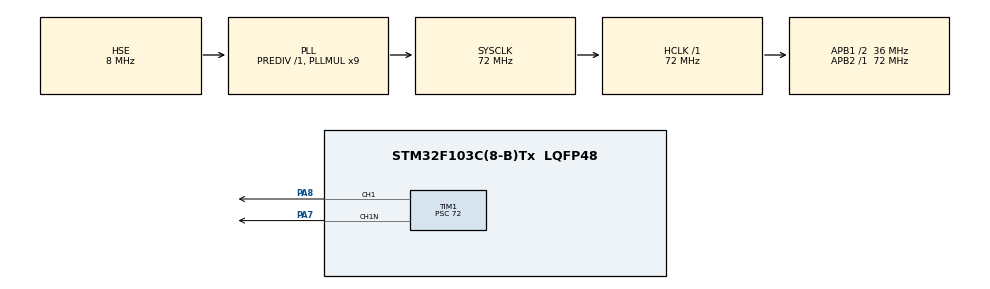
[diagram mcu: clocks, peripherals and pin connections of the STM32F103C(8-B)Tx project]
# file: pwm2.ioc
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Mcu.Family=STM32F1
Mcu.Name=STM32F103C(8-B)Tx
Mcu.Package=LQFP48
NVIC.PriorityGroup=NVIC_PRIORITYGROUP_4
PA13.Mode=Serial_Wire
PA13.Signal=SYS_JTMS-SWDIO
PA14.Mode=Serial_Wire
PA14.Signal=SYS_JTCK-SWCLK
PA7.Mode=PWM Generation1 CH1 CH1N
PA7.Signal=TIM1_CH1N
PA8.Signal=S_TIM1_CH1
PD0-OSC_IN.Mode=HSE-External-Oscillator
PD0-OSC_IN.Signal=RCC_OSC_IN
PD1-OSC_OUT.Mode=HSE-External-Oscillator
PD1-OSC_OUT.Signal=RCC_OSC_OUT
ProjectManager.HeapSize=0x200
ProjectManager.StackSize=0x400
ProjectManager.TargetToolchain=SW4STM32
RCC.AHBFreq_Value=72000000
RCC.APB1CLKDivider=RCC_HCLK_DIV2
RCC.APB1Freq_Value=36000000
RCC.APB1TimFreq_Value=72000000
RCC.APB2Freq_Value=72000000
RCC.APB2TimFreq_Value=72000000
RCC.HCLKFreq_Value=72000000
RCC.PLLMUL=RCC_PLL_MUL9
RCC.PLLSourceVirtual=RCC_PLLSOURCE_HSE
RCC.SYSCLKFreq_VALUE=72000000
RCC.SYSCLKSource=RCC_SYSCLKSOURCE_PLLCLK
RCC.USBFreq_Value=72000000
SH.S_TIM1_CH1.0=TIM1_CH1,PWM Generation1 CH1 CH1N
TIM1.Channel-PWM\ Generation1\ CH1\ CH1N=TIM_CHANNEL_1
TIM1.Period=1000
TIM1.Prescaler=72
board=custom

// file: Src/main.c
/**
  ******************************************************************************
  * @file           : main.c
  * @brief          : Main program body
  ******************************************************************************
  ** This notice applies to any and all portions of this file
  * that are not between comment pairs USER CODE BEGIN and
  * USER CODE END. Other portions of this file, whether
  * inserted by the user or by software development tools
  * are owned by their respective copyright owners.
  *
  * COPYRIGHT(c) 2018 STMicroelectronics
  *
  * Redistribution and use in source and binary forms, with or without modification,
  * are permitted provided that the following conditions are met:
  *   1. Redistributions of source code must retain the above copyright notice,
  *      this list of conditions and the following disclaimer.
  *   2. Redistributions in binary form must reproduce the above copyright notice,
  *      this list of conditions and the following disclaimer in the documentation
  *      and/or other materials provided with the distribution.
  *   3. Neither the name of STMicroelectronics nor the names of its contributors
  *      may be used to endorse or promote products derived from this software
  *      without specific prior written permission.
  *
  * THIS SOFTWARE IS PROVIDED BY THE COPYRIGHT HOLDERS AND CONTRIBUTORS "AS IS"
  * AND ANY EXPRESS OR IMPLIED WARRANTIES, INCLUDING, BUT NOT LIMITED TO, THE
  * IMPLIED WARRANTIES OF MERCHANTABILITY AND FITNESS FOR A PARTICULAR PURPOSE ARE
  * DISCLAIMED. IN NO EVENT SHALL THE COPYRIGHT HOLDER OR CONTRIBUTORS BE LIABLE
  * FOR ANY DIRECT, INDIRECT, INCIDENTAL, SPECIAL, EXEMPLARY, OR CONSEQUENTIAL
  * DAMAGES (INCLUDING, BUT NOT LIMITED TO, PROCUREMENT OF SUBSTITUTE GOODS OR
  * SERVICES; LOSS OF USE, DATA, OR PROFITS; OR BUSINESS INTERRUPTION) HOWEVER
  * CAUSED AND ON ANY THEORY OF LIABILITY, WHETHER IN CONTRACT, STRICT LIABILITY,
  * OR TORT (INCLUDING NEGLIGENCE OR OTHERWISE) ARISING IN ANY WAY OUT OF THE USE
  * OF THIS SOFTWARE, EVEN IF ADVISED OF THE POSSIBILITY OF SUCH DAMAGE.
  *
  ******************************************************************************
  */
#include "main.h"
#include "stm32f1xx_hal.h"

TIM_HandleTypeDef htim1;

/* USER CODE BEGIN PV */
/* Private variables ---------------------------------------------------------*/

/* USER CODE END PV */

void SystemClock_Config(void);
static void MX_GPIO_Init(void);
static void MX_TIM1_Init(void);
void HAL_TIM_MspPostInit(TIM_HandleTypeDef *htim);

/* USER CODE BEGIN PFP */
/* Private function prototypes -----------------------------------------------*/

/* USER CODE END PFP */

int main(void)
{
  /* USER CODE BEGIN 1 */
  uint16_t dutyCycle = 0;
  /* USER CODE END 1 */

  /* MCU Configuration----------------------------------------------------------*/

  /* Reset of all peripherals, Initializes the Flash interface and the Systick. */
  HAL_Init();

  /* Configure the system clock */
  SystemClock_Config();

  /* Initialize all configured peripherals */
  MX_GPIO_Init();
  MX_TIM1_Init();
  /* USER CODE BEGIN 2 */
  HAL_TIM_PWM_Start(&htim1,TIM_CHANNEL_1);
  HAL_TIMEx_PWMN_Start(&htim1,TIM_CHANNEL_1);
  /* USER CODE END 2 */

  /* Infinite loop */
  /* USER CODE BEGIN WHILE */
  //__HAL_TIM_SET_COMPARE(&htim1, TIM_CHANNEL_1, 500);
  while (1)
  {
	  while (dutyCycle < 1000)
	  {
		  dutyCycle ++;
		  __HAL_TIM_SET_COMPARE(&htim1, TIM_CHANNEL_1, dutyCycle);
//		  TIM3->CCR2 = dutyCycle;
		  HAL_Delay(1);
	  }
	  while (dutyCycle)
	  {
		  dutyCycle --;
		  __HAL_TIM_SET_COMPARE(&htim1, TIM_CHANNEL_1, dutyCycle);
//		  TIM3->CCR2 = dutyCycle;
		  HAL_Delay(1);
	  }
	  HAL_Delay(200);
  /* USER CODE END WHILE */

  }

}

void SystemClock_Config(void)
{

  RCC_OscInitTypeDef RCC_OscInitStruct;
  RCC_ClkInitTypeDef RCC_ClkInitStruct;

    /**Initializes the CPU, AHB and APB busses clocks
    */
  RCC_OscInitStruct.OscillatorType = RCC_OSCILLATORTYPE_HSE;
  RCC_OscInitStruct.HSEState = RCC_HSE_ON;
  RCC_OscInitStruct.HSEPredivValue = RCC_HSE_PREDIV_DIV1;
  RCC_OscInitStruct.HSIState = RCC_HSI_ON;
  RCC_OscInitStruct.PLL.PLLState = RCC_PLL_ON;
  RCC_OscInitStruct.PLL.PLLSource = RCC_PLLSOURCE_HSE;
  RCC_OscInitStruct.PLL.PLLMUL = RCC_PLL_MUL9;
  if (HAL_RCC_OscConfig(&RCC_OscInitStruct) != HAL_OK)
  {
    _Error_Handler(__FILE__, __LINE__);
  }

    /**Initializes the CPU, AHB and APB busses clocks
    */
  RCC_ClkInitStruct.ClockType = RCC_CLOCKTYPE_HCLK|RCC_CLOCKTYPE_SYSCLK
                              |RCC_CLOCKTYPE_PCLK1|RCC_CLOCKTYPE_PCLK2;
  RCC_ClkInitStruct.SYSCLKSource = RCC_SYSCLKSOURCE_PLLCLK;
  RCC_ClkInitStruct.AHBCLKDivider = RCC_SYSCLK_DIV1;
  RCC_ClkInitStruct.APB1CLKDivider = RCC_HCLK_DIV2;
  RCC_ClkInitStruct.APB2CLKDivider = RCC_HCLK_DIV1;

  if (HAL_RCC_ClockConfig(&RCC_ClkInitStruct, FLASH_LATENCY_2) != HAL_OK)
  {
    _Error_Handler(__FILE__, __LINE__);
  }

    /**Configure the Systick interrupt time
    */
  HAL_SYSTICK_Config(HAL_RCC_GetHCLKFreq()/1000);

    /**Configure the Systick
    */
  HAL_SYSTICK_CLKSourceConfig(SYSTICK_CLKSOURCE_HCLK);

  /* SysTick_IRQn interrupt configuration */
  HAL_NVIC_SetPriority(SysTick_IRQn, 0, 0);
}

/* TIM1 init function */
static void MX_TIM1_Init(void)
{

  TIM_MasterConfigTypeDef sMasterConfig;
  TIM_OC_InitTypeDef sConfigOC;
  TIM_BreakDeadTimeConfigTypeDef sBreakDeadTimeConfig;

  htim1.Instance = TIM1;
  htim1.Init.Prescaler = 72;
  htim1.Init.CounterMode = TIM_COUNTERMODE_UP;
  htim1.Init.Period = 1000;
  htim1.Init.ClockDivision = TIM_CLOCKDIVISION_DIV1;
  htim1.Init.RepetitionCounter = 0;
  htim1.Init.AutoReloadPreload = TIM_AUTORELOAD_PRELOAD_DISABLE;
  if (HAL_TIM_PWM_Init(&htim1) != HAL_OK)
  {
    _Error_Handler(__FILE__, __LINE__);
  }

  sMasterConfig.MasterOutputTrigger = TIM_TRGO_RESET;
  sMasterConfig.MasterSlaveMode = TIM_MASTERSLAVEMODE_DISABLE;
  if (HAL_TIMEx_MasterConfigSynchronization(&htim1, &sMasterConfig) != HAL_OK)
  {
    _Error_Handler(__FILE__, __LINE__);
  }

  sConfigOC.OCMode = TIM_OCMODE_PWM1;
  sConfigOC.Pulse = 0;
  sConfigOC.OCPolarity = TIM_OCPOLARITY_HIGH;
  sConfigOC.OCNPolarity = TIM_OCNPOLARITY_HIGH;
  sConfigOC.OCFastMode = TIM_OCFAST_DISABLE;
  sConfigOC.OCIdleState = TIM_OCIDLESTATE_RESET;
  sConfigOC.OCNIdleState = TIM_OCNIDLESTATE_RESET;
  if (HAL_TIM_PWM_ConfigChannel(&htim1, &sConfigOC, TIM_CHANNEL_1) != HAL_OK)
  {
    _Error_Handler(__FILE__, __LINE__);
  }

  sBreakDeadTimeConfig.OffStateRunMode = TIM_OSSR_DISABLE;
  sBreakDeadTimeConfig.OffStateIDLEMode = TIM_OSSI_DISABLE;
  sBreakDeadTimeConfig.LockLevel = TIM_LOCKLEVEL_OFF;
  sBreakDeadTimeConfig.DeadTime = 0;
  sBreakDeadTimeConfig.BreakState = TIM_BREAK_DISABLE;
  sBreakDeadTimeConfig.BreakPolarity = TIM_BREAKPOLARITY_HIGH;
  sBreakDeadTimeConfig.AutomaticOutput = TIM_AUTOMATICOUTPUT_DISABLE;
  if (HAL_TIMEx_ConfigBreakDeadTime(&htim1, &sBreakDeadTimeConfig) != HAL_OK)
  {
    _Error_Handler(__FILE__, __LINE__);
  }

  HAL_TIM_MspPostInit(&htim1);

}

/** Configure pins as
        * Analog
        * Input
        * Output
        * EVENT_OUT
        * EXTI
*/
static void MX_GPIO_Init(void)
{

  /* GPIO Ports Clock Enable */
  __HAL_RCC_GPIOD_CLK_ENABLE();
  __HAL_RCC_GPIOA_CLK_ENABLE();

}

void _Error_Handler(char *file, int line)
{
  while(1)
  {
  }
}

/************************ (C) COPYRIGHT STMicroelectronics *****END OF FILE****/
